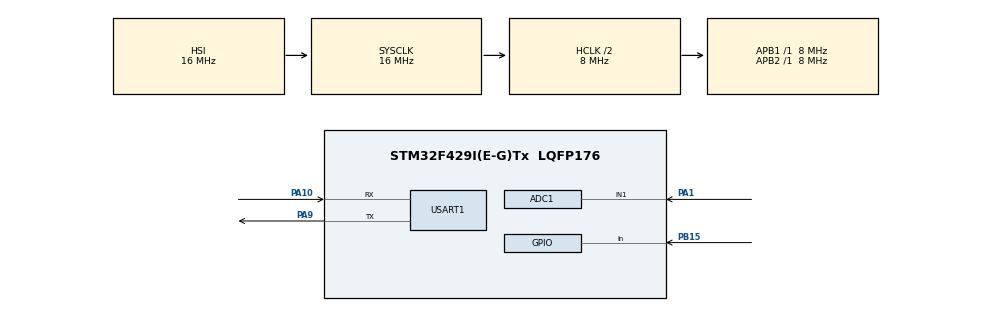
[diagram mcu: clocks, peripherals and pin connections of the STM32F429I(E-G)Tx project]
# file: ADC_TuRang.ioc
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ADC1.Channel-1\#ChannelRegularConversion=ADC_CHANNEL_1
ADC1.NbrOfConversion=1
ADC1.NbrOfConversionFlag=1
ADC1.Rank-1\#ChannelRegularConversion=1
ADC1.SamplingTime-1\#ChannelRegularConversion=ADC_SAMPLETIME_15CYCLES
ADC1.master=1
Mcu.Family=STM32F4
Mcu.Name=STM32F429I(E-G)Tx
Mcu.Package=LQFP176
NVIC.PriorityGroup=NVIC_PRIORITYGROUP_4
NVIC.USART1_IRQn=true\:0\:0\:false\:false\:true\:true\:true\:true
PA1.Signal=ADCx_IN1
PA10.Mode=Asynchronous
PA10.Signal=USART1_RX
PA9.Mode=Asynchronous
PA9.Signal=USART1_TX
PB15.Signal=GPIO_Input
ProjectManager.HeapSize=0x200
ProjectManager.StackSize=0x400
ProjectManager.TargetToolchain=MDK-ARM V5.32
RCC.AHBCLKDivider=RCC_SYSCLK_DIV2
RCC.AHBFreq_Value=8000000
RCC.APB1Freq_Value=8000000
RCC.APB1TimFreq_Value=8000000
RCC.APB2Freq_Value=8000000
RCC.APB2TimFreq_Value=8000000
RCC.CortexFreq_Value=8000000
RCC.HCLKFreq_Value=8000000
RCC.HSE_VALUE=25000000
RCC.HSI_VALUE=16000000
RCC.LSE_VALUE=32768
RCC.SYSCLKFreq_VALUE=16000000
RCC.VCOOutputFreq_Value=192000000
SH.ADCx_IN1.0=ADC1_IN1,IN1
USART1.VirtualMode=VM_ASYNC
board=custom

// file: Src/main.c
/* USER CODE BEGIN Header */
/**
  ******************************************************************************
  * @file           : main.c
  * @brief          : Main program body
  ******************************************************************************
  * @attention
  *
  * Copyright (c) 2024 STMicroelectronics.
  * All rights reserved.
  *
  * This software is licensed under terms that can be found in the LICENSE file
  * in the root directory of this software component.
  * If no LICENSE file comes with this software, it is provided AS-IS.
  *
  ******************************************************************************
  */
/* USER CODE END Header */
#include "main.h"
#include "adc.h"
#include "usart.h"
#include "gpio.h"

/* USER CODE BEGIN Includes */
#include <stdio.h>
#include <string.h>
/* USER CODE END Includes */

void SystemClock_Config(void);

int main(void)
{

  /* MCU Configuration--------------------------------------------------------*/

  /* Reset of all peripherals, Initializes the Flash interface and the Systick. */
  HAL_Init();

  /* Configure the system clock */
  SystemClock_Config();

  /* Initialize all configured peripherals */
  MX_GPIO_Init();
  MX_ADC1_Init();
  MX_USART1_UART_Init();
  /* USER CODE BEGIN 2 */
	//启动ADC常规序列
	HAL_ADC_Start(&hadc1);
  /* USER CODE END 2 */

  /* Infinite loop */
  /* USER CODE BEGIN WHILE */
  while (1)
  {
		//启动ADC常规序列
		HAL_ADC_Start(&hadc1);
		//轮询等待常规序列转换完成
		HAL_ADC_PollForConversion(&hadc1,HAL_MAX_DELAY);

		//获取常规序列转换结果
		uint32_t result = HAL_ADC_GetValue(&hadc1);
		//result 范围是0 - 4096 正好对应电压是0-3.3V
		float volt = result/4096.0 * 3.3;

		char buffer[32] = {0};
		snprintf(buffer,sizeof(buffer),"result:%.2fV\n",volt);
		HAL_UART_Transmit(&huart1,(uint8_t *)buffer,sizeof(buffer),HAL_MAX_DELAY);
		HAL_Delay(1000);
//		//读取D0口的状态
//		GPIO_PinState state = HAL_GPIO_ReadPin(GPIOB,GPIO_PIN_15);
//		HAL_Delay(3000);
//
//		//发送信息到串口
//		HAL_UART_Transmit(&huart1,(uint8_t *)&state,sizeof(state),HAL_MAX_DELAY);
    /* USER CODE END WHILE */

  }
}

void SystemClock_Config(void)
{
  RCC_OscInitTypeDef RCC_OscInitStruct = {0};
  RCC_ClkInitTypeDef RCC_ClkInitStruct = {0};

  /** Configure the main internal regulator output voltage
  */
  __HAL_RCC_PWR_CLK_ENABLE();
  __HAL_PWR_VOLTAGESCALING_CONFIG(PWR_REGULATOR_VOLTAGE_SCALE3);

  /** Initializes the RCC Oscillators according to the specified parameters
  * in the RCC_OscInitTypeDef structure.
  */
  RCC_OscInitStruct.OscillatorType = RCC_OSCILLATORTYPE_HSI;
  RCC_OscInitStruct.HSIState = RCC_HSI_ON;
  RCC_OscInitStruct.HSICalibrationValue = RCC_HSICALIBRATION_DEFAULT;
  RCC_OscInitStruct.PLL.PLLState = RCC_PLL_NONE;
  if (HAL_RCC_OscConfig(&RCC_OscInitStruct) != HAL_OK)
  {
    Error_Handler();
  }

  /** Initializes the CPU, AHB and APB buses clocks
  */
  RCC_ClkInitStruct.ClockType = RCC_CLOCKTYPE_HCLK|RCC_CLOCKTYPE_SYSCLK
                              |RCC_CLOCKTYPE_PCLK1|RCC_CLOCKTYPE_PCLK2;
  RCC_ClkInitStruct.SYSCLKSource = RCC_SYSCLKSOURCE_HSI;
  RCC_ClkInitStruct.AHBCLKDivider = RCC_SYSCLK_DIV2;
  RCC_ClkInitStruct.APB1CLKDivider = RCC_HCLK_DIV1;
  RCC_ClkInitStruct.APB2CLKDivider = RCC_HCLK_DIV1;

  if (HAL_RCC_ClockConfig(&RCC_ClkInitStruct, FLASH_LATENCY_0) != HAL_OK)
  {
    Error_Handler();
  }
}

void Error_Handler(void)
{
  __disable_irq();
  while (1)
  {
  }
}
